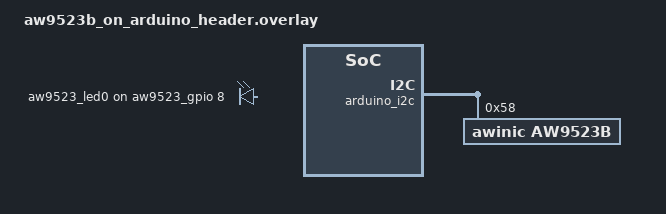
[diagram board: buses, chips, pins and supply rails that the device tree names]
&arduino_i2c {
	status = "okay";
	aw9523b@58 {
		status = "okay";
		reg = <0x58>;
		compatible = "awinic,aw9523b";

		aw9523_gpio: gpio {
			compatible = "awinic,aw9523b-gpio";
			gpio-controller;
			#gpio-cells = <2>;
			port0-push-pull;
			int-gpios = <&arduino_header 18 (GPIO_ACTIVE_LOW|GPIO_PULL_UP)>;
			reset-gpios = <&arduino_header 19 (GPIO_ACTIVE_LOW|GPIO_PULL_UP)>;
		};
	};
};

/ {
	leds {
		aw9523_led0: aw9523_led0 {
			gpios = < &aw9523_gpio 8 0>;
		};
	};

	aliases {
		led0 = &aw9523_led0;
	};
};
